# R7FA4W1AD register map
Vendor: Renesas; Series: RA4; File version: 1.0
CPU: CM4 r0p1, little endian, MPU, FPU, VTOR, 4 interrupt priority bits
Registers are 8-bit, read-write, reset 0x0 unless marked. A register's access mark holds for its fields unless they carry their own. Offsets are from the block's base; [hi:lo] are bit positions; {n}, {i} and the like mark numbered series.

## ICU — Interrupt Controller
Base 0x40006000
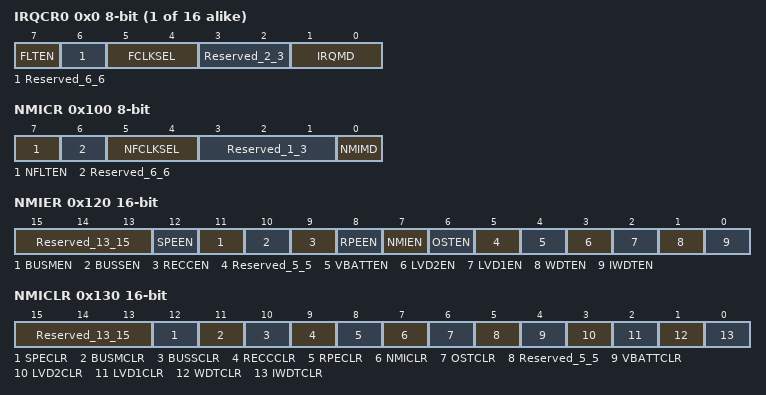
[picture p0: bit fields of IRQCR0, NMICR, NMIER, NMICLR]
{0x0+i} IRQCR{i} (i=0..15) — IRQ Control Register {i}
  [7] FLTEN — IRQ Digital Filter Enable
  [6] Reserved_6_6 — This bit is read as 0. The write value should be 0.
  [5:4] FCLKSEL — IRQ Digital Filter Sampling Clock Select
  [3:2] Reserved_2_3 — These bits are read as 00. The write value should be 00.
  [1:0] IRQMD — IRQ Detection Sense Select
0x100 NMICR — NMI Pin Interrupt Control Register
  [7] NFLTEN — NMI Digital Filter Enable
  [6] Reserved_6_6 — This bit is read as 0. The write value should be 0.
  [5:4] NFCLKSEL — NMI Digital Filter Sampling Clock Select
  [3:1] Reserved_1_3 — These bits are read as 000. The write value should be 000.
  [0] NMIMD — NMI Detection Set
0x120 NMIER 16-bit — Non,Maskable Interrupt Enable Register
  [15:13] Reserved_13_15 — These bits are read as 000. The write value should be 000.
  [12] SPEEN — CPU Stack pointer monitor Interrupt Enable
  [11] BUSMEN — MPU Bus Master Error Interrupt Enable
  [10] BUSSEN — MPU Bus Slave Error Interrupt Enable
  [9] RECCEN — RAM ECC Error Interrupt Enable
  [8] RPEEN — RAM Parity Error Interrupt Enable
  [7] NMIEN — NMI Pin Interrupt Enable
  [6] OSTEN — Oscillation Stop Detection Interrupt Enable
  [5] Reserved_5_5 — This bit is read as 0. The write value should be 0.
  [4] VBATTEN — VBATT monitor Interrupt Enable
  [3] LVD2EN — Voltage,Monitoring 2 Interrupt Enable
  [2] LVD1EN — Voltage,Monitoring 1 Interrupt Enable
  [1] WDTEN — WDT Underflow/Refresh Error Interrupt Enable
  [0] IWDTEN — IWDT Underflow/Refresh Error Interrupt Enable
0x130 NMICLR 16-bit — Non,Maskable Interrupt Status Clear Register
  [15:13] Reserved_13_15 — These bits are read as 000. The write value should be 000.
  [12] SPECLR wo — CPU Stack Pointer Monitor Interrupt Clear
  [11] BUSMCLR wo — Bus Master Error Clear
  [10] BUSSCLR wo — Bus Slave Error Clear
  [9] RECCCLR wo — SRAM ECC Error Clear
  [8] RPECLR wo — SRAM Parity Error Clear
  [7] NMICLR wo — NMI Clear
  [6] OSTCLR wo — OST Clear
  [5] Reserved_5_5 — This bit is read as 0. The write value should be 0.
  [4] VBATTCLR wo — VBATT Clear
  [3] LVD2CLR wo — LVD2 Clear
  [2] LVD1CLR wo — LVD1 Clear
  [1] WDTCLR wo — WDT Clear
  [0] IWDTCLR wo — IWDT Clear
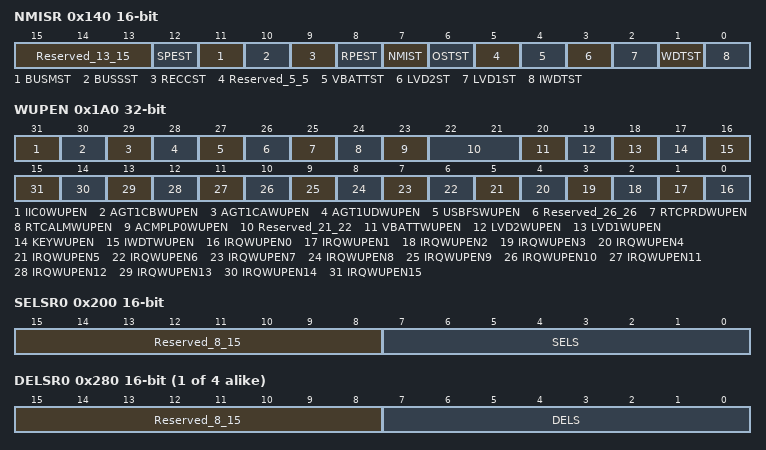
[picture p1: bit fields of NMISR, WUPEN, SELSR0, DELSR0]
0x140 NMISR 16-bit ro — Non,Maskable Interrupt Status Register
  [15:13] Reserved_13_15 — These bits are read as 000.
  [12] SPEST — CPU Stack pointer monitor Interrupt Status Flag
  [11] BUSMST — MPU Bus Master Error Interrupt Status Flag
  [10] BUSSST — MPU Bus Slave Error Interrupt Status Flag
  [9] RECCST — RAM ECC Error Interrupt Status Flag
  [8] RPEST — RAM Parity Error Interrupt Status Flag
  [7] NMIST — NMI Status Flag
  [6] OSTST — Oscillation Stop Detection Interrupt Status Flag
  [5] Reserved_5_5 — This bit is read as 0.
  [4] VBATTST — VBATT monitor Interrupt Status Flag
  [3] LVD2ST — Voltage,Monitoring 2 Interrupt Status Flag
  [2] LVD1ST — Voltage,Monitoring 1 Interrupt Status Flag
  [1] WDTST — WDT Underflow/Refresh Error Status Flag
  [0] IWDTST — IWDT Underflow/Refresh Error Status Flag
0x1A0 WUPEN 32-bit — Wake Up Interrupt Enable Register
  [31] IIC0WUPEN — IIC0 address match interrupt S/W standby returns enable
  [30] AGT1CBWUPEN — AGT1 compare match B interrupt S/W standby returns enable
  [29] AGT1CAWUPEN — AGT1 compare match A interrupt S/W standby returns enable
  [28] AGT1UDWUPEN — AGT1 underflow interrupt S/W standby returns enable
  [27] USBFSWUPEN — USBFS interrupt S/W standby returns enable
  [26] Reserved_26_26 — This bit is read as 0. The write value should be 0.
  [25] RTCPRDWUPEN — RCT period interrupt S/W standby returns enable
  [24] RTCALMWUPEN — RTC alarm interrupt S/W standby returns enable
  [23] ACMPLP0WUPEN — ACMPLP0 interrupt S/W standby returns enable
  [22:21] Reserved_21_22 — These bits are read as 00. The write value should be 00.
  [20] VBATTWUPEN — VBATT monitor interrupt S/W standby returns enable
  [19] LVD2WUPEN — LVD2 interrupt S/W standby returns enable
  [18] LVD1WUPEN — LVD1 interrupt S/W standby returns enable
  [17] KEYWUPEN — Key interrupt S/W standby returns enable
  [16] IWDTWUPEN — IWDT interrupt S/W standby returns enable
  [n] IRQWUPEN{n} (n=0..15) — IRQ{n} interrupt S/W standby returns enable
0x200 SELSR0 16-bit — Snooze Event Link Setting Register
  [15:8] Reserved_8_15 — These bits are read as 00000000. The write value should be 00000000.
  [7:0] SELS — SYS Event Link Select
{0x280+4i} DELSR{i} (i=0..3) 16-bit — DMAC Event Link Setting Register {i}
  [15:8] Reserved_8_15 — These bits are read as 00000000. The write value should be 00000000.
  [7:0] DELS — Event selection to DMAC Start request
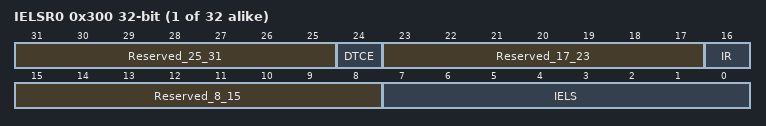
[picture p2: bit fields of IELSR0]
{0x300+4i} IELSR{i} (i=0..31) 32-bit — ICU Event Link Setting Register {i}
  [31:25] Reserved_25_31 — These bits are read as 0000000. The write value should be 0000000.
  [24] DTCE — DTC Activation Enable
  [23:17] Reserved_17_23 — These bits are read as 0000000. The write value should be 0000000.
  [16] IR — Interrupt Status Flag
  [15:8] Reserved_8_15 — These bits are read as 00000000. The write value should be 00000000.
  [7:0] IELS — ICU Event selection to NVICSet the number for the event signal to be linked .
